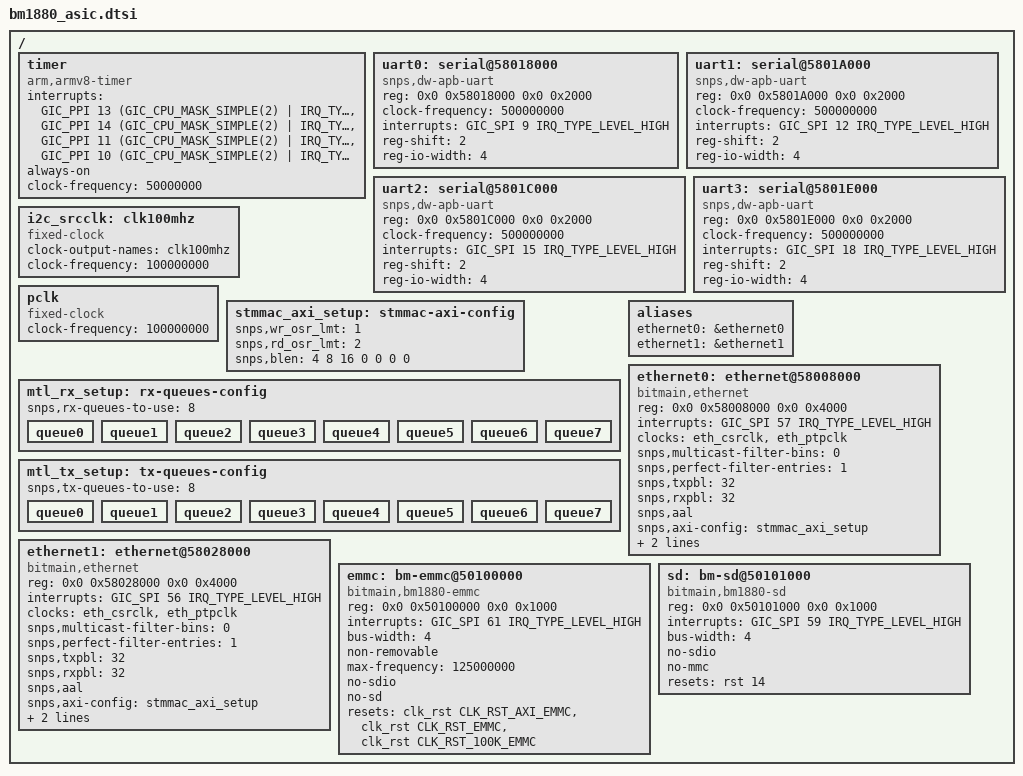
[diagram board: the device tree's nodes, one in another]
#include "bm1880.dtsi"

/ {
	timer {
		interrupts = <GIC_PPI 13 (GIC_CPU_MASK_SIMPLE(2) | IRQ_TYPE_LEVEL_LOW)>,
			<GIC_PPI 14 (GIC_CPU_MASK_SIMPLE(2) | IRQ_TYPE_LEVEL_LOW)>,
			<GIC_PPI 11 (GIC_CPU_MASK_SIMPLE(2) | IRQ_TYPE_LEVEL_LOW)>,
			<GIC_PPI 10 (GIC_CPU_MASK_SIMPLE(2) | IRQ_TYPE_LEVEL_LOW)>;
		always-on;
		clock-frequency = <50000000>;
		compatible = "arm,armv8-timer";
	};

	uart0: serial@58018000 {
		compatible = "snps,dw-apb-uart";
		reg = <0x0 0x58018000 0x0 0x2000>;
		clock-frequency = <500000000>;
		interrupts = <GIC_SPI 9 IRQ_TYPE_LEVEL_HIGH>;
		reg-shift = <2>;
		reg-io-width = <4>;
		//dmas = <&dmac 10 1 1 /* read channel */
		//	&dmac 11 1 1>; /* write channel */
		//dma-names = "rx", "tx";
	};

	uart1: serial@5801A000 {
		compatible = "snps,dw-apb-uart";
		reg = <0x0 0x5801A000 0x0 0x2000>;
		clock-frequency = <500000000>;
		interrupts = <GIC_SPI 12 IRQ_TYPE_LEVEL_HIGH>;
		reg-shift = <2>;
		reg-io-width = <4>;
	};

	uart2: serial@5801C000 {
		compatible = "snps,dw-apb-uart";
		reg = <0x0 0x5801C000 0x0 0x2000>;
		clock-frequency = <500000000>;
		interrupts = <GIC_SPI 15 IRQ_TYPE_LEVEL_HIGH>;
		reg-shift = <2>;
		reg-io-width = <4>;
	};

	uart3: serial@5801E000 {
		compatible = "snps,dw-apb-uart";
		reg = <0x0 0x5801E000 0x0 0x2000>;
		clock-frequency = <500000000>;
		interrupts = <GIC_SPI 18 IRQ_TYPE_LEVEL_HIGH>;
		reg-shift = <2>;
		reg-io-width = <4>;
	};

	i2c_srcclk: clk100mhz {
		clock-output-names = "clk100mhz";
		clock-frequency = <100000000>;
		#clock-cells = <0x0>;
		compatible = "fixed-clock";
	};

	pclk: pclk {
		#clock-cells = <0>;
		compatible = "fixed-clock";
		clock-frequency = <100000000>;
	};

	stmmac_axi_setup: stmmac-axi-config {
		snps,wr_osr_lmt = <1>;
		snps,rd_osr_lmt = <2>;
		snps,blen = <4 8 16 0 0 0 0>;
	};

	mtl_rx_setup: rx-queues-config {
		snps,rx-queues-to-use = <8>;
		queue0 {};
		queue1 {};
		queue2 {};
		queue3 {};
		queue4 {};
		queue5 {};
		queue6 {};
		queue7 {};
	};

	mtl_tx_setup: tx-queues-config {
		snps,tx-queues-to-use = <8>;
		queue0 {};
		queue1 {};
		queue2 {};
		queue3 {};
		queue4 {};
		queue5 {};
		queue6 {};
		queue7 {};
	};

	aliases {
		ethernet0 = &ethernet0;
		ethernet1 = &ethernet1;
	};

	ethernet0: ethernet@58008000 {
		compatible = "bitmain,ethernet";
		reg = <0x0 0x58008000 0x0 0x4000>;
		interrupts = <GIC_SPI 57 IRQ_TYPE_LEVEL_HIGH>;
		interrupt-names = "macirq";
		clock-names = "stmmaceth", "ptp_ref";
		clocks = <&eth_csrclk>, <&eth_ptpclk> ;

		/* no hash filter and perfect filter support */
		snps,multicast-filter-bins = <0>;
		snps,perfect-filter-entries = <1>;

		snps,txpbl = <32>;
		snps,rxpbl = <32>;
		snps,aal;

		snps,axi-config = <&stmmac_axi_setup>;
		snps,mtl-rx-config = <&mtl_rx_setup>;
		snps,mtl-tx-config = <&mtl_tx_setup>;

	};

	ethernet1: ethernet@58028000 {
		compatible = "bitmain,ethernet";
		reg = <0x0 0x58028000 0x0 0x4000>;
		interrupts = <GIC_SPI 56 IRQ_TYPE_LEVEL_HIGH>;
		interrupt-names = "macirq";
		clock-names = "stmmaceth", "ptp_ref";
		clocks = <&eth_csrclk>, <&eth_ptpclk> ;

		/* no hash filter and perfect filter support */
		snps,multicast-filter-bins = <0>;
		snps,perfect-filter-entries = <1>;

		snps,txpbl = <32>;
		snps,rxpbl = <32>;
		snps,aal;

		snps,axi-config = <&stmmac_axi_setup>;
		snps,mtl-rx-config = <&mtl_rx_setup>;
		snps,mtl-tx-config = <&mtl_tx_setup>;

	};

	emmc:bm-emmc@50100000 {
		compatible = "bitmain,bm1880-emmc";
		reg = <0x0 0x50100000 0x0 0x1000>;
		reg-names = "core_mem";
		interrupts = <GIC_SPI 61 IRQ_TYPE_LEVEL_HIGH>;
		bus-width = <4>;
		non-removable;
		max-frequency = <125000000>;
		no-sdio;
		no-sd;
		resets = <&clk_rst CLK_RST_AXI_EMMC>,
			 <&clk_rst CLK_RST_EMMC>,
			 <&clk_rst CLK_RST_100K_EMMC>;
		reset-names = "axi_emmc", "emmc", "100k_emmc";
	};

	sd:bm-sd@50101000 {
		compatible = "bitmain,bm1880-sd";
		reg = <0x0 0x50101000 0x0 0x1000>;
		reg-names = "core_mem";
		interrupts = <GIC_SPI 59 IRQ_TYPE_LEVEL_HIGH>;
		bus-width = <4>;
		no-sdio;
		no-mmc;
		resets = <&rst 14>;
		reset-names = "sdio";
	};

	//Disable it if the NAND board is installed
#if 0
	/delete-node/ hpnfc@500C0000;
#endif
};
